# PT32x066xx register map
File version: 0.3
Registers are 32-bit, read-write, reset 0x0 unless marked. A register's access mark holds for its fields unless they carry their own. Offsets are from the block's base; lines under a group give offsets from that group; [hi:lo] are bit positions; {n}, {i} and the like mark numbered series; 'fields as' and 'values as' point back to an identical list; <NAME> marks a mode.

## Memory map
0x40000000 IFMC size 0x800 — On-chip flash memory controller
0x40001000 TIM2 size 0x400 — Basic timer
0x40001400 TIM3 size 0x400 — Basic timer
0x40001C00 TIM4 size 0x400 — Low power timer
0x40002800 BEEP size 0x400
0x40003000 IWDG size 0x800 — Independent Watchdog
0x40003C00 CRC size 0x400 — Cyclic redundancy check
0x40004000 LPUART0 size 0x400 — Lowpower Universal Asynchronous Receiver Transmitter
0x40004400 UART0 size 0x400 — Universal Asynchronous Receiver Transmitter
0x40004C00 LPUART1 size 0x400
0x40005400 I2C0 size 0x400 — Inter Integrated Circuit
0x40006C00 LPTIM size 0x400 — Low Power timer
0x40008000 DDS size 0x400 — Direct Digital Synthesis
0x40008400 IRTIM size 0x400 — Infrared Timer
0x4000F000 DMA size 0x400 — Direct memory access
0x40011800 DAC0 size 0x400 — Digital-to-Analog Converter
0x40011C00 DAC1 size 0x400 — Digital-to-Analog Converter
0x40012000 SDADC0 size 0x400 — Segma Delta Analog-to-digital converters
0x40013000 SPI0 size 0x400 — Serial peripheral interface
0x40013800 UART1 size 0x400 — Universal Asynchronous Receiver Transmitter
0x40013C00 RTC size 0x400 — Real Time Clock
0x40014400 TIM5 size 0x400 — Advanced timer
0x40014800 TIM6 size 0x400
0x40015000 LCD size 0x800 — Liquid Crystal Display
0x40015C00 OPA0 size 0x100 — Operational Amplifier
0x40015D00 OPA1 size 0x100 — Operational Amplifier
0x40020000 RCC size 0x400 — Reset and clock control
0x40020400 PWR size 0x400 — Power control
0x40020800 ES size 0x400 — Device Electronic Signature
0x40020C00 SYSCFG size 0x400 — System Configuration
0x48000000 GPIOA size 0x400 — General purpose I/O
0x48000100 AFIOA size 0x400 — Alternate function
0x48000200 EXTIA size 0x400 — External interrupt
0x48001000 GPIOB size 0x400
0x48001100 AFIOB size 0x400
0x48001200 EXTIB size 0x400
0x48002000 GPIOC size 0x400
0x48002100 AFIOC size 0x400
0x48002200 EXTIC size 0x400
0x48003000 GPIOD size 0x400
0x48003100 AFIOD size 0x400
0x48003200 EXTID size 0x400
0x48004000 GPIOE size 0x400
0x48004100 AFIOE size 0x400
0x48004200 EXTIE size 0x400

## CRC — Cyclic redundancy check
Base 0x40003C00
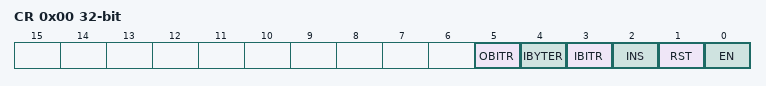
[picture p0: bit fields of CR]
0x00 CR access per field — Control Register
  [5] OBITR rw — CRC output bit sequence reversal
  [4] IBYTER rw — CRC input byte sequence reversal
  [3] IBITR rw — CRC input bit sequence reversal
  [2] INS rw — CRC input selection
  [1] RST wo — CRC reset control
  [0] EN rw — CRC enable
0x04 SEEDR reset 0xFFFF — Seed Register
  [15:0] SEED — CRC seed
0x08 POLYR reset 0x8005 — Polynomial Register
  [15:0] POLY — CRC poly
0x0C DINR wo — Data Input Register
  [15:0] DIN — CRC data input
0x10 DOUT ro — Data Output Register
  [15:0] DOUT — CRC data output

## PWR — Power control
Base 0x40020400
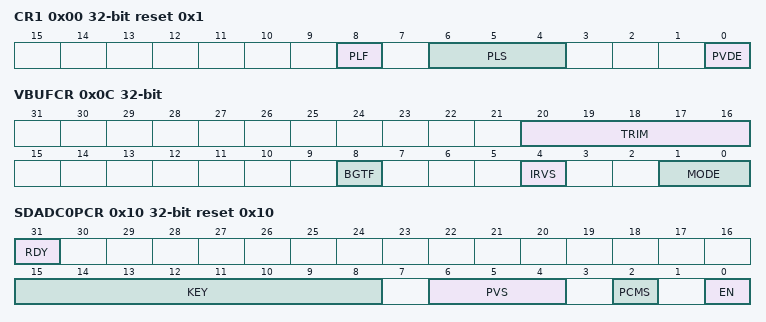
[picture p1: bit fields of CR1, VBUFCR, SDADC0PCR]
0x00 CR1 access per field reset 0x1 — Control Register 1
  [8] PLF ro — PVD level status flag
  [6:4] PLS rw — PVD level selection
  [0] PVDE rw — Power voltage detection enable
0x08 SR ro — Status Register
  [0] LPRDY — LPR ready flag
0x0C VBUFCR access per field — VREFBUF Control Register
  [20:16] TRIM rw — BG2v0 offset trimming value
  [8] BGTF ro — BG2v0 offset trimming value source flag
  [4] IRVS rw — Internal reference voltage selection
  [1:0] MODE rw — Voltage reference buffer mode
0x10 SDADC0PCR access per field reset 0x10 — SDADC0 Power Control Register
  [31] RDY ro — SDADC0 power ready flag
  [15:8] KEY wo — Key value
  [6:4] PVS rw — SDADC0 power voltage selection
  [2] PCMS rw — SDADC0 power filter capacitor mode selection
  [0] EN rw — SDADC0 power enable

## SYSCFG — System Configuration
Base 0x40020C00
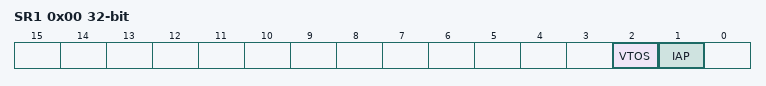
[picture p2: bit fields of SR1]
0x00 SR1 access per field — Status Register 1
  [2] VTOS rw — Interrupt vector table location selection flag
  [1] IAP ro — IAP enable flag
0x14 IAPAR — IAP Address Register
  [31:0] ADDR — IAP address
0x18 SVTOR ro — SRAM Interrupt Vector Table Address Register
  [31:0] ADDR — SRAM interrupt vector table address
0x1C CR wo — Control Register
  [31:0] KEY — Key value
